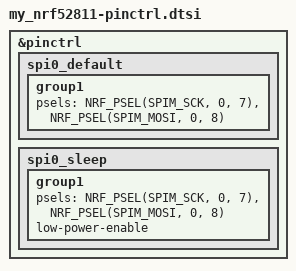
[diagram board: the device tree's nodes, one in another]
/*
 * nRF52811 pinctrl configuration.
 * EPD SPI0: SCK=P0.07, MOSI=P0.08, MISO unused.
 */

&pinctrl {
	spi0_default: spi0_default {
		group1 {
			psels = <NRF_PSEL(SPIM_SCK, 0, 7)>,
				<NRF_PSEL(SPIM_MOSI, 0, 8)>;
		};
	};

	spi0_sleep: spi0_sleep {
		group1 {
			psels = <NRF_PSEL(SPIM_SCK, 0, 7)>,
				<NRF_PSEL(SPIM_MOSI, 0, 8)>;
			low-power-enable;
		};
	};
};
